# FM33G0XX register map
File version: 1.0
CPU: SC000 r1p0, little endian, no MPU, no FPU, 3 interrupt priority bits
Registers are 32-bit, read-write, reset 0x0 unless marked. A register's access mark holds for its fields unless they carry their own. Offsets are from the block's base; [hi:lo] are bit positions; {n}, {i} and the like mark numbered series; 'fields as' and 'values as' point back to an identical list.

## DMA — Peripheral DMA, Direct Memory Access
Base 0x40000400
0x00 GLOBALCTRL — Global Control Register
  [0] DMAEN — DMA Global enable bit
    0=DISABLE (DMA is disable); 1=ENABLE (DMA is enable)
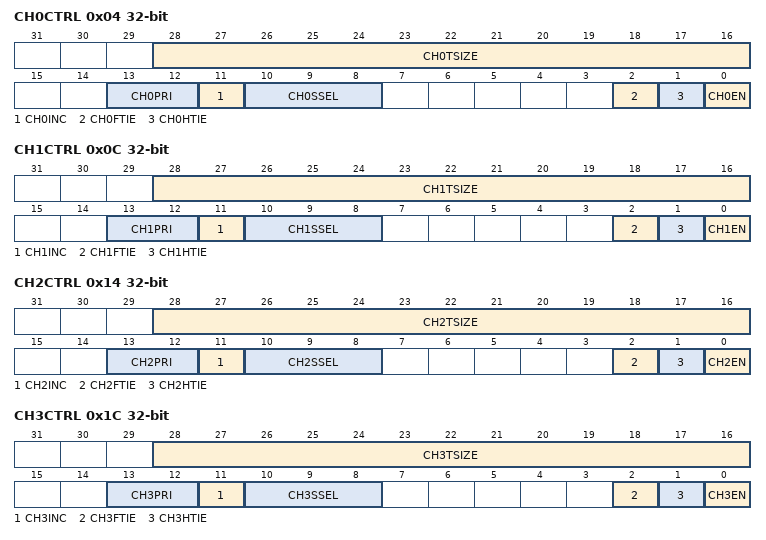
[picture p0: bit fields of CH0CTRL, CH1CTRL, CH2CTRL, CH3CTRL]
0x04 CH0CTRL — DMA CH0 control Register
  [28:16] CH0TSIZE — channel0 transmit size setting
  [13:12] CH0PRI — channel0 priority setting
    0=LOW (channel0's priority is low); 1=Medium (channel0's priority is Medium); 2=High (channel0's priority is High); 3=Very High (channel0's priority is Very High)
  [11] CH0INC — channel0 RAM address increase setting
    0=DECREASE (channel0 RAM address decrease); 1=INCREASE (channel0 RAM address increase)
  [10:8] CH0SSEL — channel0 periph source select
    0=ET4_CAP (etimer4 capture data); 1=ET2_CAP (etimer2 capture data); 2=BT34_CAP (btimer34 capture data); 3=ET3_CAP (etimer3 capture data); 4=BT12_CAP (btimer12 capture data); 5=CRC_OUT (CRC output data); 6=AES_IN (AES input data); 7=ADC_OUT (ADC output data)
  [2] CH0FTIE — channel0 full transmit interrupt enable bit
    0=DISABLE (CH0 full transmit interrupt disable); 1=ENABLE (CH0 full transmit interrupt enable)
  [1] CH0HTIE — channel0 half transmit interrupt enable bit
    0=DISABLE (CH0 half transmit interrupt disable); 1=ENABLE (CH0 half transmit interrupt enable)
  [0] CH0EN — channel0 enable bit
    0=DISABLE (CH0 disable); 1=ENABLE (CH0 enable)
{0x8+8i} CH{i}RAMAD (i=0..6) — DMA channel{i} RAM address Register
  [14:0] CH{i}RAMAD — CH{i} RAM address
0x0C CH1CTRL — DMA CH1 control Register
  [28:16] CH1TSIZE — channel1 transmit size setting
  [13:12] CH1PRI — channel1 priority setting
    0=LOW (channel1's priority is low); 1=Medium (channel1's priority is Medium); 2=High (channel1's priority is High); 3=Very High (channel1's priority is Very High)
  [11] CH1INC — channel1 RAM address increase setting
    0=DECREASE (channel1 RAM address decrease); 1=INCREASE (channel1 RAM address increase)
  [10:8] CH1SSEL — channel1 periph source select
    0=ET1_CAP (etimer1 capture data); 1=AES_OUT (AES output data); 2=I2C_RX (I2C receive data); 3=U78160_RX (U78160 receive data); 4=UART3_RX (UART3 receive data); 5=UART0_RX (UART0 receive data); 6=SPI0_RX (SPI0 receive data); 7=ADC_OUT (ADC output data)
  [2] CH1FTIE — channel1 full transmit interrupt enable bit
    0=DISABLE (CH1 full transmit interrupt disable); 1=ENABLE (CH1 full transmit interrupt enable)
  [1] CH1HTIE — channel1 half transmit interrupt enable bit
    0=DISABLE (CH1 half transmit interrupt disable); 1=ENABLE (CH1 half transmit interrupt enable)
  [0] CH1EN — channel1 enable bit
    0=DISABLE (CH1 disable); 1=ENABLE (CH1 enable)
0x14 CH2CTRL — DMA CH2 control Register
  [28:16] CH2TSIZE — channel2 transmit size setting
  [13:12] CH2PRI — channel2 priority setting
    0=LOW (channel2's priority is low); 1=Medium (channel2's priority is Medium); 2=High (channel2's priority is High); 3=Very High (channel2's priority is Very High)
  [11] CH2INC — channel2 RAM address increase setting
    0=DECREASE (channel2 RAM address decrease); 1=INCREASE (channel2 RAM address increase)
  [10:8] CH2SSEL — channel2 periph source select
    0=ET3_CAP (etimer3 capture data); 1=BT12_CAP (Basetimer12 capture data); 2=AES_OUT (AES output data); 3=I2C_TX (I2C transmit data); 4=U78160_TX (U78160 transmit data); 5=UART3_TX (UART3 transmit data); 6=UART0_TX (UART0 transmit data); 7=SPI0_TX (SPI0 transmit data)
  [2] CH2FTIE — channel2 full transmit interrupt enable bit
    0=DISABLE (CH2 full transmit interrupt disable); 1=ENABLE (CH2 full transmit interrupt enable)
  [1] CH2HTIE — channel2 half transmit interrupt enable bit
    0=DISABLE (CH2 half transmit interrupt disable); 1=ENABLE (CH2 half transmit interrupt enable)
  [0] CH2EN — channel2 enable bit
    0=DISABLE (CH2 disable); 1=ENABLE (CH2 enable)
0x1C CH3CTRL — DMA CH3 control Register
  [28:16] CH3TSIZE — channel3 transmit size setting
  [13:12] CH3PRI — channel3 priority setting
    0=LOW (channel3's priority is low); 1=Medium (channel3's priority is Medium); 2=High (channel3's priority is High); 3=Very High (channel3's priority is Very High)
  [11] CH3INC — channel3 RAM address increase setting
    0=DECREASE (channel3 RAM address decrease); 1=INCREASE (channel3 RAM address increase)
  [10:8] CH3SSEL — channel3 periph source select
    0=BT34_CAP (Basetimer34 capture data); 1=ET1_CAP (Etimer1 capture data); 2=I2C_TX (I2C transmit data); 3=U78161_RX (U78161 receive data); 4=UART4_RX (UART4 receive data); 5=UART1_RX (UART1 receive data); 6=UART0_RX (UART0 receive data); 7=SPI1_RX (SPI1 receive data)
  [2] CH3FTIE — channel3 full transmit interrupt enable bit
    0=DISABLE (CH3 full transmit interrupt disable); 1=ENABLE (CH3 full transmit interrupt enable)
  [1] CH3HTIE — channel3 half transmit interrupt enable bit
    0=DISABLE (CH3 half transmit interrupt disable); 1=ENABLE (CH3 half transmit interrupt enable)
  [0] CH3EN — channel3 enable bit
    0=DISABLE (CH3 disable); 1=ENABLE (CH3 enable)
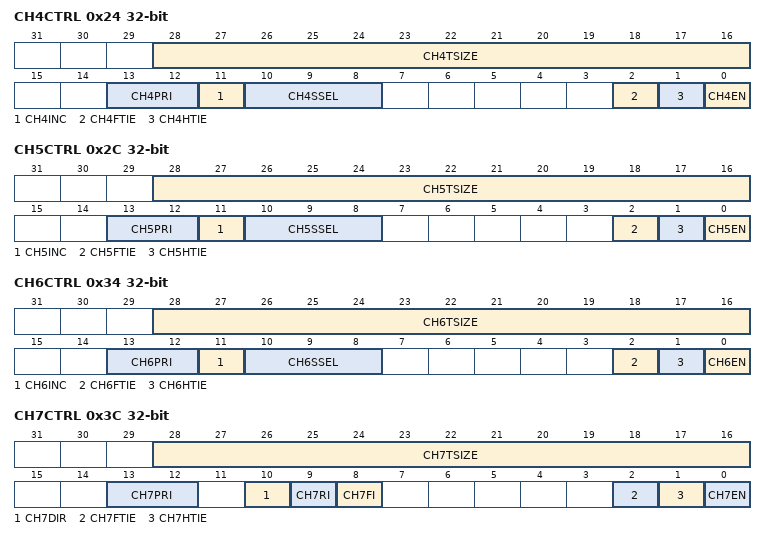
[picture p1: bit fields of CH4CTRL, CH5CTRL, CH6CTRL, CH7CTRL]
0x24 CH4CTRL — DMA CH4 control Register
  [28:16] CH4TSIZE — channel4 transmit size setting
  [13:12] CH4PRI — channel4 priority setting
    0=LOW (channel4's priority is low); 1=Medium (channel4's priority is Medium); 2=High (channel4's priority is High); 3=Very High (channel4's priority is Very High)
  [11] CH4INC — channel4 RAM address increase setting
    0=DECREASE (channel4 RAM address decrease); 1=INCREASE (channel4 RAM address increase)
  [10:8] CH4SSEL — channel4 periph source select
    0=ET2_CAP (Etimer2 capture data); 1=AES_IN (AES input data); 2=I2C_RX (I2C receive data); 3=U78161_TX (U78161 transmit data); 4=UART4_TX (UART4 transmit data); 5=UART1_TX (UART1 transmit data); 6=UART0_TX (UART0 transmit data); 7=SPI1_TX (SPI1 transmit data)
  [2] CH4FTIE — channel4 full transmit interrupt enable bit
    0=DISABLE (CH4 full transmit interrupt disable); 1=ENABLE (CH4 full transmit interrupt enable)
  [1] CH4HTIE — channel4 half transmit interrupt enable bit
    0=DISABLE (CH4 half transmit interrupt disable); 1=ENABLE (CH4 half transmit interrupt enable)
  [0] CH4EN — channel4 enable bit
    0=DISABLE (CH4 disable); 1=ENABLE (CH4 enable)
0x2C CH5CTRL — DMA CH5 control Register
  [28:16] CH5TSIZE — channel5 transmit size setting
  [13:12] CH5PRI — channel5 priority setting
    0=LOW (channel5's priority is low); 1=Medium (channel5's priority is Medium); 2=High (channel5's priority is High); 3=Very High (channel5's priority is Very High)
  [11] CH5INC — channel5 RAM address increase setting
    0=DECREASE (channel5 RAM address decrease); 1=INCREASE (channel5 RAM address increase)
  [10:8] CH5SSEL — channel5 periph source select
    0=LPUART_RX (LPTimer capture data); 1=U78161_RX (U78161 receive data); 2=U78160_RX (U78160 receive data); 3=UART5_RX (UART5 receive data); 4=UART2_RX (UART2 receive data); 5=UART1_RX (UART1 receive data); 6=SPI2_RX (SPI2 receive data); 7=SPI0_RX (SPI0 receive data)
  [2] CH5FTIE — channel5 full transmit interrupt enable bit
    0=DISABLE (CH5 full transmit interrupt disable); 1=ENABLE (CH5 full transmit interrupt enable)
  [1] CH5HTIE — channel5 half transmit interrupt enable bit
    0=DISABLE (CH5 half transmit interrupt disable); 1=ENABLE (CH5 half transmit interrupt enable)
  [0] CH5EN — channel5 enable bit
    0=DISABLE (CH5 disable); 1=ENABLE (CH5 enable)
0x34 CH6CTRL — DMA CH6 control Register
  [28:16] CH6TSIZE — channel6 transmit size setting
  [13:12] CH6PRI — channel6 priority setting
    0=LOW (channel6's priority is low); 1=Medium (channel6's priority is Medium); 2=High (channel6's priority is High); 3=Very High (channel6's priority is Very High)
  [11] CH6INC — channel6 RAM address increase setting
    0=DECREASE (channel6 RAM address decrease); 1=INCREASE (channel6 RAM address increase)
  [10:8] CH6SSEL — channel6 periph source select
    0=LPUART_TX (LPTimer capture data); 1=U7816T1_TX (U78161 transmit data); 2=U78160_TX (U78160 transmit data); 3=UART5_TX (UART5 transmit data); 4=UART2_TX (UART2 transmit data); 5=UART1_TX (UART1 transmit data); 6=SPI2_TX (SPI2 transmit data); 7=SPI0_TX (SPI0 transmit data)
  [2] CH6FTIE — channel6 full transmit interrupt enable bit
    0=DISABLE (CH6 full transmit interrupt disable); 1=ENABLE (CH6 full transmit interrupt enable)
  [1] CH6HTIE — channel6 half transmit interrupt enable bit
    0=DISABLE (CH6 half transmit interrupt disable); 1=ENABLE (CH6 half transmit interrupt enable)
  [0] CH6EN — channel6 enable bit
    0=DISABLE (CH6 disable); 1=ENABLE (CH6 enable)
0x3C CH7CTRL — DMA CH7 control Register
  [28:16] CH7TSIZE — channel7 transmit size setting(fixed size 64 when transmits from ram to flash )
  [13:12] CH7PRI — channel7 priority setting
    0=LOW (channel7's priority is low); 1=Medium (channel7's priority is Medium); 2=High (channel7's priority is High); 3=Very High (channel7's priority is Very High)
  [10] CH7DIR — channel7 transmit direction setting
    0=RAM2FLASH (from RAM to flash); 1=FLASH2RAM (FROM flash to RAM)
  [9] CH7RI — channel7 RAM address increase setting
    0=DECREASE (channel7 RAM address decrease); 1=INCREASE (channel7 RAM address increase)
  [8] CH7FI — channel7 flash address increase setting
    0=DECREASE (channel7 flash address decrease); 1=INCREASE (channel7 flash address increase)
  [2] CH7FTIE — channel7 full transmit interrupt enable bit
    0=DISABLE (CH7 full transmit interrupt disable); 1=ENABLE (CH7 full transmit interrupt enable)
  [1] CH7HTIE — channel7 half transmit interrupt enable bit
    0=DISABLE (CH7 half transmit interrupt disable); 1=ENABLE (CH7 half transmit interrupt enable)
  [0] CH7EN — channel7 enable bit
    0=DISABLE (CH7 disable); 1=ENABLE (CH7 enable)
0x40 CH7FLSAD — DMA channel7 flash address Register
  [15:0] CH7FLSAD — CH7 flash address
0x44 CH7RAMAD — DMA channel7 RAM address Register
  [12:0] CH7RAMAD — CH7 RAM address
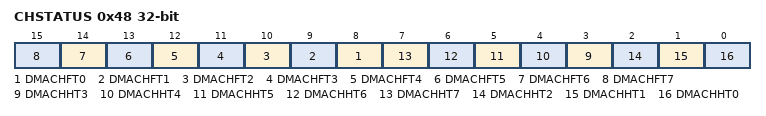
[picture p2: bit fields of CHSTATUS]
0x48 CHSTATUS — DMA status Register
  [n+8] DMACHFT{n} (n=0..7) — channel{n} transmit status bit
    0=NOT_FINISH (channel{n} transmit - not start/not finish); 1=FINISH (channel{n} transmit - finish)
  [n] DMACHHT{n} (n=3..7) — channel{n} half transmit status bit
    0=NOT_FINISH (channel{n} half transmit - not start/not finish); 1=FINISH (channel{n} half transmit - finish)
  [2] DMACHHT2 — channel2 half transmit status bit
    0=NOT_FINISH (channel1 half transmit - not start/not finish); 1=FINISH (channel1 half transmit - finish)
  [1] DMACHHT1 — channel1 half transmit status bit
    values as DMACHHT2
  [0] DMACHHT0 — channel0 half transmit status bit
    0=NOT_FINISH (channel0 half transmit - not start/not finish); 1=FINISH (channel0 half transmit - finish)
